# STM32H747xx register map
File version: 1.0
Registers are 32-bit, access not given, reset 0x0 unless marked. A register's access mark holds for its fields unless they carry their own. Offsets are from the block's base; [hi:lo] are bit positions; {n}, {i} and the like mark numbered series; 'fields as' and 'values as' point back to an identical list.

## GPV
Base 0x51000000
{0x1FC0+4i} AXI_PERIPH_ID_{i} (i=4..7)
{0x1FE0+4i} AXI_PERIPH_ID_{i} (i=0..3)
{0x1FF0+4i} AXI_COMP_ID_{i} (i=0..3)
{0x1008+0x1000*i} AXI_TARG{i}_FN_MOD_ISS_BM (i=1..7)
0x2024 AXI_TARG1_FN_MOD2
0x202C AXI_TARG1_FN_MOD_LB
0x2108 AXI_TARG1_FN_MOD
0x3024 AXI_TARG2_FN_MOD2
0x302C AXI_TARG2_FN_MOD_LB
0x3108 AXI_TARG2_FN_MOD
0x8024 AXI_TARG7_FN_MOD2
0x802C AXI_TARG7_FN_MOD_LB
0x8108 AXI_TARG7_FN_MOD
0x42024 AXI_INI1_FN_MOD2
0x42028 AXI_INI1_FN_MOD_AHB
{0x41100+0x1000*i} AXI_INI{i}_READ_QOS (i=1..7)
{0x41104+0x1000*i} AXI_INI{i}_WRITE_QOS (i=1..7)
{0x41108+0x1000*i} AXI_INI{i}_FN_MOD (i=1..7)
0x44024 AXI_INI3_FN_MOD2
0x44028 AXI_INI3_FN_MOD_AHB

## FLASH
Base 0x52002000
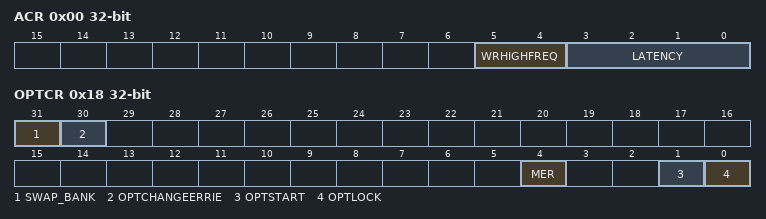
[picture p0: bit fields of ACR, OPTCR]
0x00 ACR
  [5:4] WRHIGHFREQ, [3:0] LATENCY
0x04 KEYR1
0x08 OPTKEYR
0x0C CR1
0x10 SR1
0x14 CCR1
0x18 OPTCR
  [31] SWAP_BANK, [30] OPTCHANGEERRIE, [4] MER, [1] OPTSTART, [0] OPTLOCK
0x1C OPTSR_CUR
0x20 OPTSR_PRG
0x24 OPTCCR
  [30] CLR_OPTCHANGEERR
0x28 PRAR_CUR1
0x2C PRAR_PRG1
0x30 SCAR_CUR1
0x34 SCAR_PRG1
0x38 WPSN_CUR1
0x3C WPSN_PRG1
0x40 BOOT7_CUR
0x44 BOOT7_PRG
0x48 BOOT4_CUR
0x4C BOOT4_PRG
0x50 CRCCR1
0x54 CRCSADD1
0x58 CRCEADD1
0x5C CRCDATA
  [31:0] CRC_DATA
0x60 ECC_FA1
0x104 KEYR2
0x10C CR2
0x110 SR2
0x114 CCR2
0x128 PRAR_CUR2
0x12C PRAR_PRG2
0x130 SCAR_CUR2
0x134 SCAR_PRG2
0x138 WPSN_CUR2
0x13C WPSN_PRG2
0x150 CRCCR2
0x154 CRCSADD2
0x158 CRCEADD2
0x15C CRCDATA2
0x160 ECC_FA2

## FMC_Bank1_R
Base 0x52004000
0x00 BTCR.0
0x04 BTCR.1
0x08 BTCR.2
0x0C BTCR.3
0x10 BTCR.4
0x14 BTCR.5
0x18 BTCR.6
0x1C BTCR.7

## FMC_Bank2_R
Base 0x52004060
0x00 PCR2
0x04 SR2
0x08 PMEM2
0x0C PATT2
0x14 ECCR2

## FMC_Bank3_R
Base 0x52004080
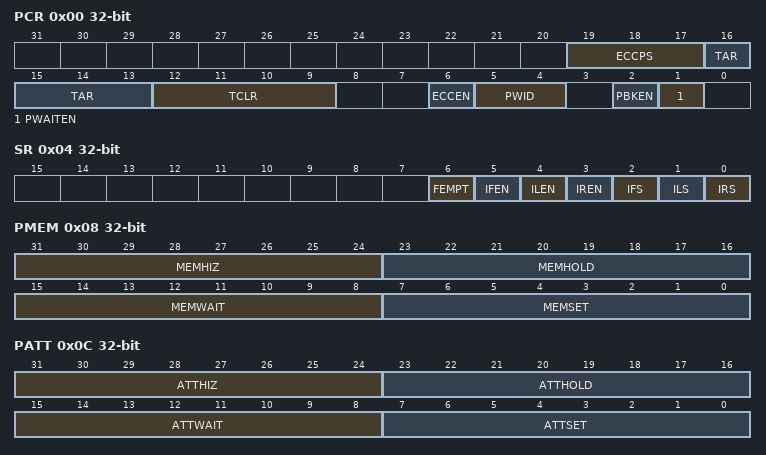
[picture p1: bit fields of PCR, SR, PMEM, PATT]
0x00 PCR
  [19:17] ECCPS, [16:13] TAR, [12:9] TCLR, [6] ECCEN, [5:4] PWID, [2] PBKEN, [1] PWAITEN
0x04 SR
  [6] FEMPT, [5] IFEN, [4] ILEN, [3] IREN, [2] IFS, [1] ILS, [0] IRS
0x08 PMEM
  [31:24] MEMHIZ, [23:16] MEMHOLD, [15:8] MEMWAIT, [7:0] MEMSET
0x0C PATT
  [31:24] ATTHIZ, [23:16] ATTHOLD, [15:8] ATTWAIT, [7:0] ATTSET
0x14 ECCR

## FMC_Bank1E_R
Base 0x52004104
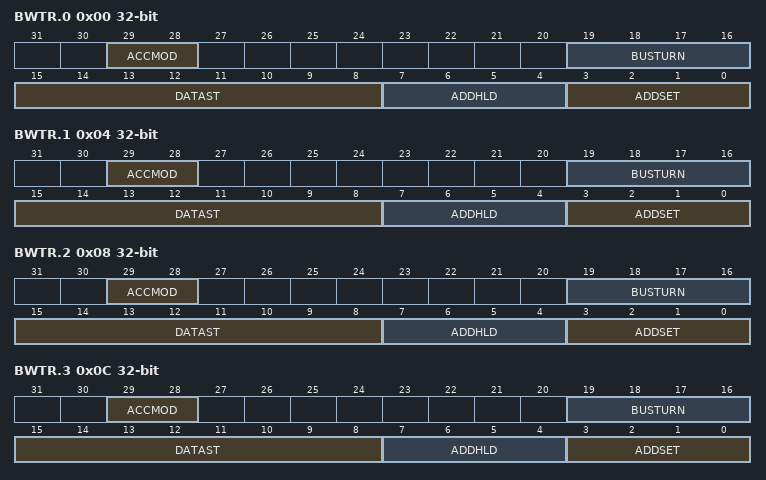
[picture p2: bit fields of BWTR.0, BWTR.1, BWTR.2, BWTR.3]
0x00 BWTR.0
  [29:28] ACCMOD, [19:16] BUSTURN, [15:8] DATAST, [7:4] ADDHLD, [3:0] ADDSET
0x04 BWTR.1
  fields as BWTR.0
0x08 BWTR.2
  fields as BWTR.0
0x0C BWTR.3
  fields as BWTR.0
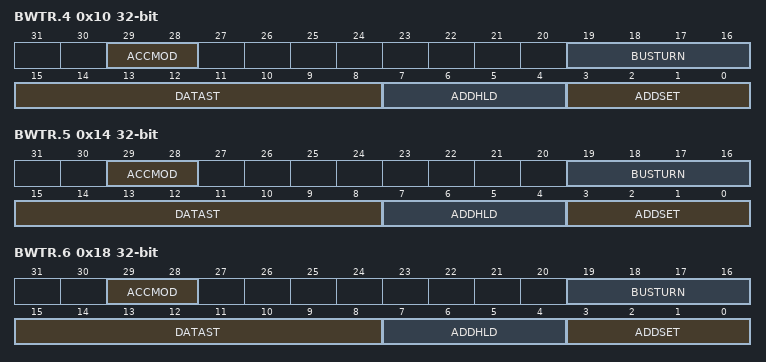
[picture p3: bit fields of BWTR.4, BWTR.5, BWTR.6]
0x10 BWTR.4
  fields as BWTR.0
0x14 BWTR.5
  fields as BWTR.0
0x18 BWTR.6
  fields as BWTR.0

## FMC_Bank5_6_R
Base 0x52004140
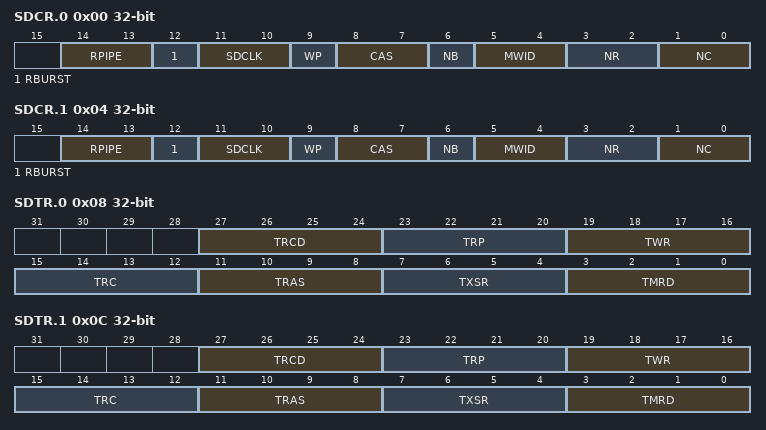
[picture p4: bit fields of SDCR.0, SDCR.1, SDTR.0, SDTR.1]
0x00 SDCR.0
  [14:13] RPIPE, [12] RBURST, [11:10] SDCLK, [9] WP, [8:7] CAS, [6] NB, [5:4] MWID, [3:2] NR, [1:0] NC
0x04 SDCR.1
  fields as SDCR.0
0x08 SDTR.0
  [27:24] TRCD, [23:20] TRP, [19:16] TWR, [15:12] TRC, [11:8] TRAS, [7:4] TXSR, [3:0] TMRD
0x0C SDTR.1
  fields as SDTR.0
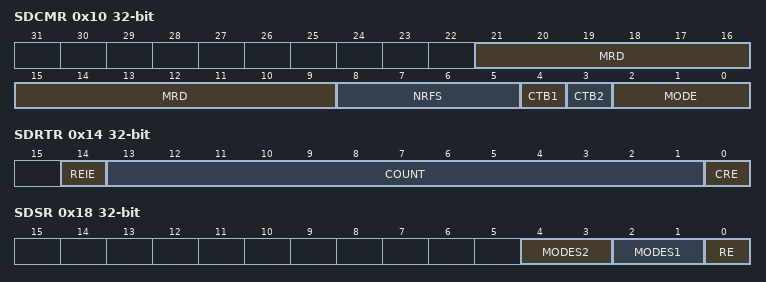
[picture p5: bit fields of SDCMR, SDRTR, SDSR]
0x10 SDCMR
  [21:9] MRD, [8:5] NRFS, [4] CTB1, [3] CTB2, [2:0] MODE
0x14 SDRTR
  [14] REIE, [13:1] COUNT, [0] CRE
0x18 SDSR
  [4:3] MODES2, [2:1] MODES1, [0] RE

## QUADSPI
Base 0x52005000
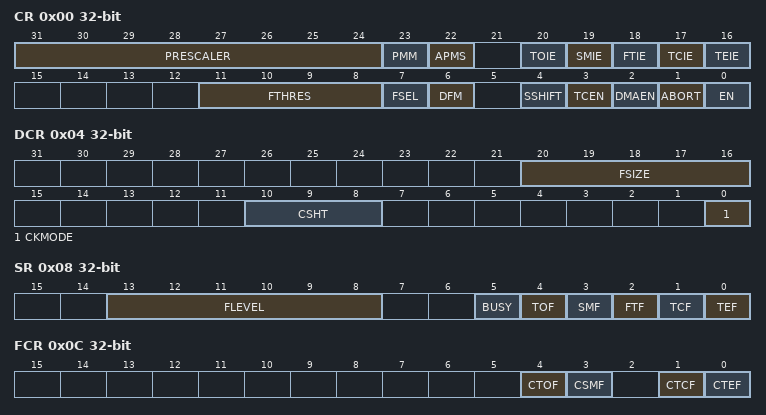
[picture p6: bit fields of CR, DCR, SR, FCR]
0x00 CR
  [31:24] PRESCALER, [23] PMM, [22] APMS, [20] TOIE, [19] SMIE, [18] FTIE, [17] TCIE, [16] TEIE, [11:8] FTHRES, [7] FSEL, [6] DFM, [4] SSHIFT, [3] TCEN, [2] DMAEN, [1] ABORT, [0] EN
0x04 DCR
  [20:16] FSIZE, [10:8] CSHT, [0] CKMODE
0x08 SR
  [13:8] FLEVEL, [5] BUSY, [4] TOF, [3] SMF, [2] FTF, [1] TCF, [0] TEF
0x0C FCR
  [4] CTOF, [3] CSMF, [1] CTCF, [0] CTEF
0x10 DLR
  [31:0] DL
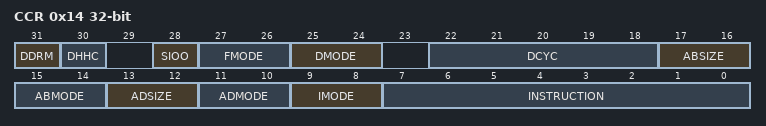
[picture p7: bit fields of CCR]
0x14 CCR
  [31] DDRM, [30] DHHC, [28] SIOO, [27:26] FMODE, [25:24] DMODE, [22:18] DCYC, [17:16] ABSIZE, [15:14] ABMODE, [13:12] ADSIZE, [11:10] ADMODE, [9:8] IMODE, [7:0] INSTRUCTION
0x18 AR
  [31:0] ADDRESS
0x1C ABR
  [31:0] ALTERNATE
0x20 DR
  [31:0] DATA
0x24 PSMKR
  [31:0] MASK
0x28 PSMAR
  [31:0] MATCH
0x2C PIR
  [15:0] INTERVAL
0x30 LPTR
  [15:0] TIMEOUT

## EXTI
Base 0x58000000
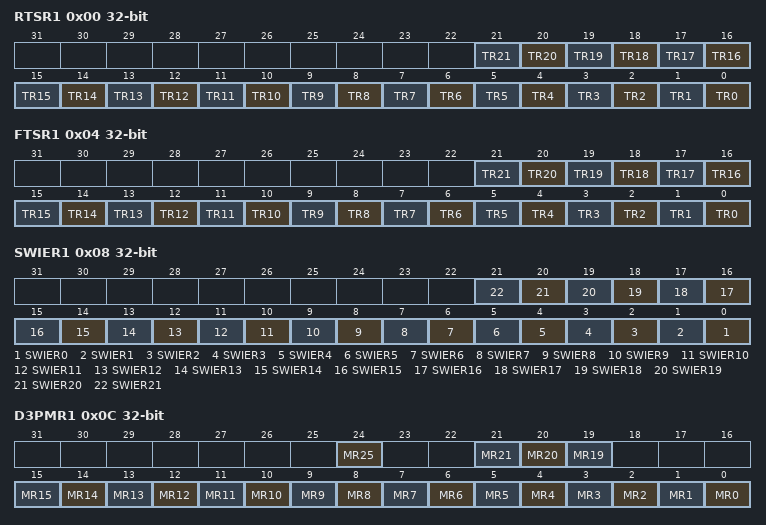
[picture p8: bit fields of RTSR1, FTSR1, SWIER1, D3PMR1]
0x00 RTSR1
  [n] TR{n} (n=0..21)
0x04 FTSR1
  [n] TR{n} (n=0..21)
0x08 SWIER1
  [n] SWIER{n} (n=0..21)
0x0C D3PMR1
  [24] MR25, [21] MR21, [20] MR20, [19] MR19, [n] MR{n} (n=0..15)
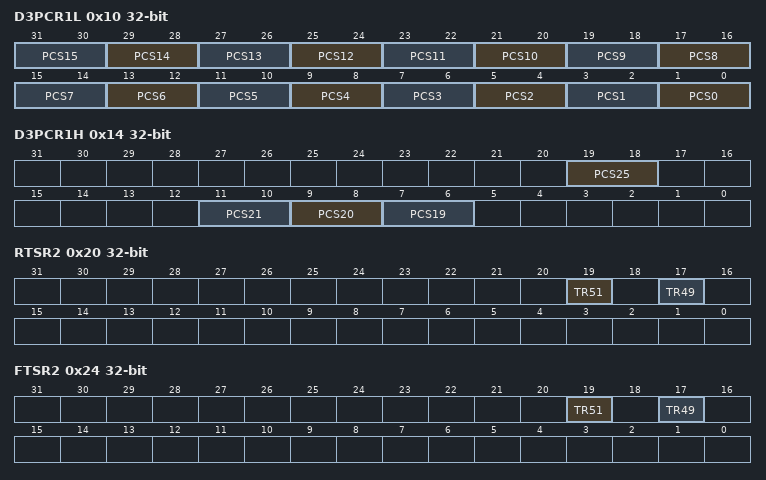
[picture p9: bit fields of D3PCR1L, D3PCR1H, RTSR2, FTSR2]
0x10 D3PCR1L
  [2n+1:2n] PCS{n} (n=0..15)
0x14 D3PCR1H
  [19:18] PCS25, [11:10] PCS21, [9:8] PCS20, [7:6] PCS19
0x20 RTSR2
  [19] TR51, [17] TR49
0x24 FTSR2
  [19] TR51, [17] TR49
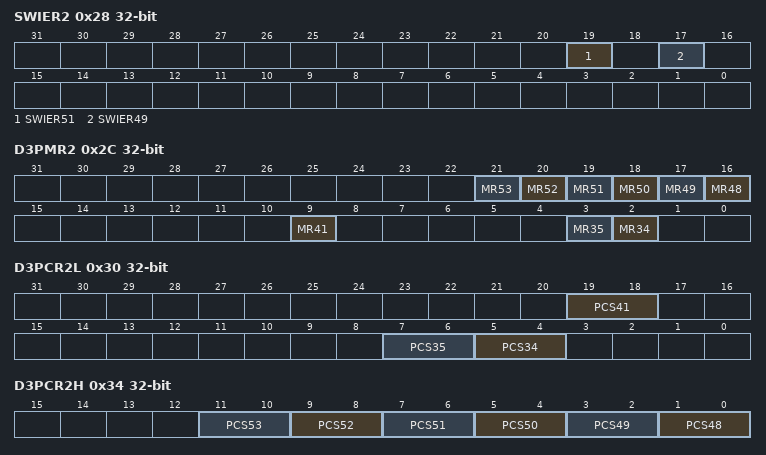
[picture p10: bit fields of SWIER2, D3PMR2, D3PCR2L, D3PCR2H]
0x28 SWIER2
  [19] SWIER51, [17] SWIER49
0x2C D3PMR2
  [n-32] MR{n} (n=48..53), [9] MR41, [3] MR35, [2] MR34
0x30 D3PCR2L
  [19:18] PCS41, [7:6] PCS35, [5:4] PCS34
0x34 D3PCR2H
  [2n-95:2n-96] PCS{n} (n=48..53)
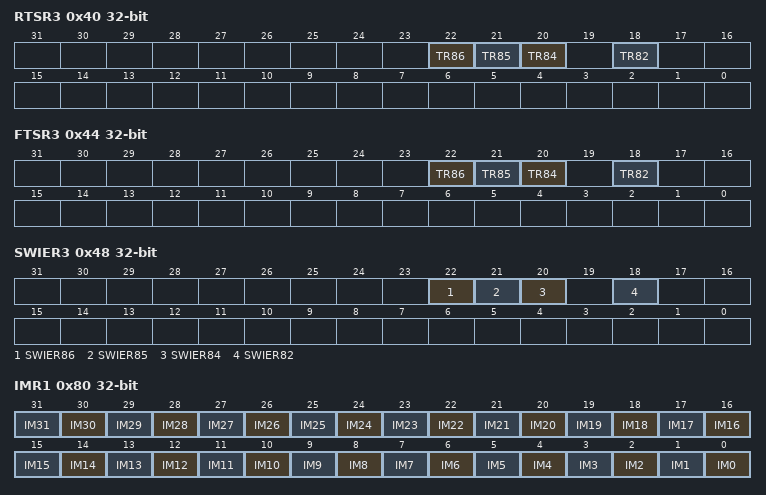
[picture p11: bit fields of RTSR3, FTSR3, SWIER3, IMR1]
0x40 RTSR3
  [22] TR86, [21] TR85, [20] TR84, [18] TR82
0x44 FTSR3
  [22] TR86, [21] TR85, [20] TR84, [18] TR82
0x48 SWIER3
  [22] SWIER86, [21] SWIER85, [20] SWIER84, [18] SWIER82
0x4C D3PMR3
0x50 D3PCR3L
0x54 D3PCR3H
0x80 IMR1
  [n] IM{n} (n=0..31)
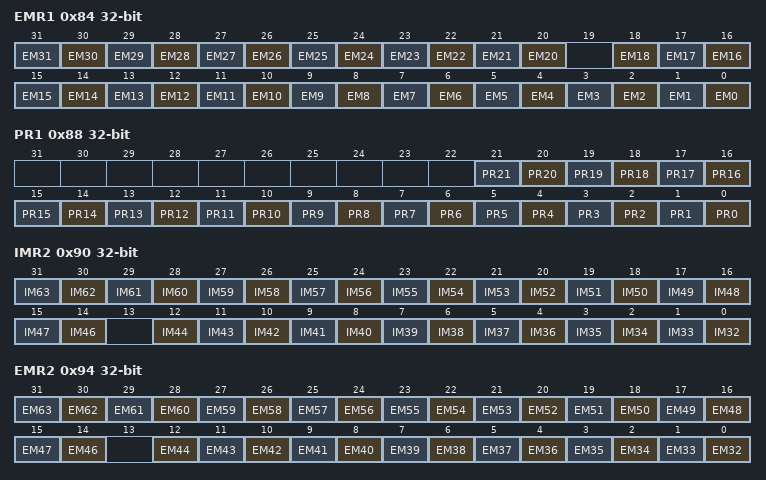
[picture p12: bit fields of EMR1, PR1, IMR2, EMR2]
0x84 EMR1
  [n] EM{n} (n=20..31), [n] EM{n} (n=0..18)
0x88 PR1
  [n] PR{n} (n=0..21)
0x90 IMR2
  [n-32] IM{n} (n=46..63), [n-32] IM{n} (n=32..44)
0x94 EMR2
  [n-32] EM{n} (n=46..63), [n-32] EM{n} (n=32..44)
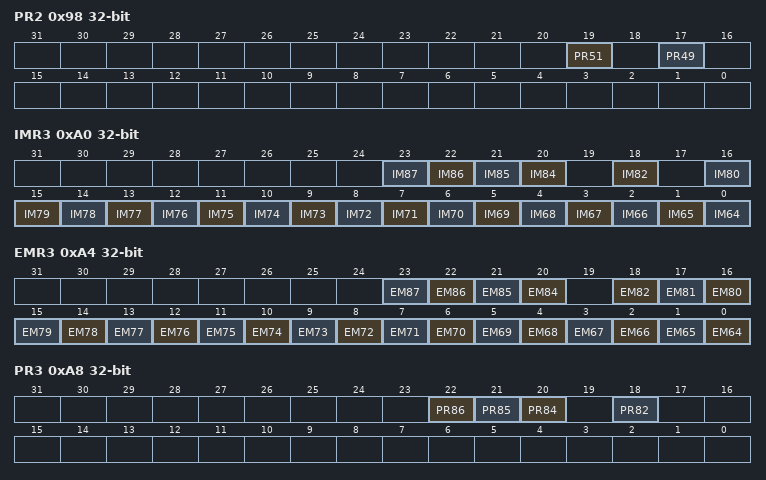
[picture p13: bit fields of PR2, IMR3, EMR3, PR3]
0x98 PR2
  [19] PR51, [17] PR49
0xA0 IMR3
  [n-64] IM{n} (n=84..87), [18] IM82, [n-64] IM{n} (n=64..80)
0xA4 EMR3
  [n-64] EM{n} (n=84..87), [n-64] EM{n} (n=64..82)
0xA8 PR3
  [22] PR86, [21] PR85, [20] PR84, [18] PR82
{0xB0+0x10*i} C2IMR{i} (i=1..3)
{0xB4+0x10*i} C2EMR{i} (i=1..3)
{0xB8+0x10*i} C2PR{i} (i=1..3)
